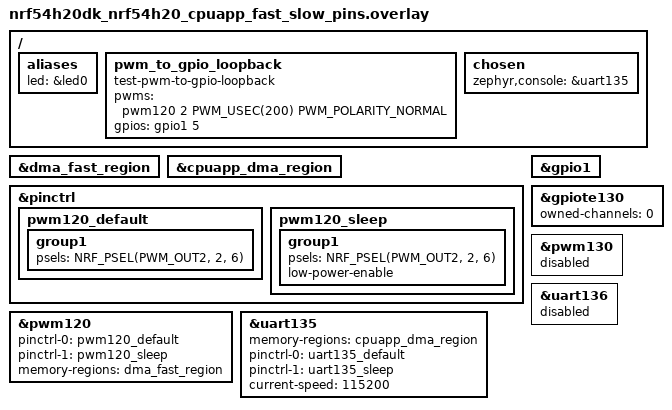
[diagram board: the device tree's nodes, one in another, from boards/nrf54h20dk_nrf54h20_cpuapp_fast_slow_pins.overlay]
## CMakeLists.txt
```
#
# Copyright (c) 2024 Nordic Semiconductor ASA
#
# SPDX-License-Identifier: LicenseRef-Nordic-5-Clause
#

cmake_minimum_required(VERSION 3.20.0)

find_package(Zephyr REQUIRED HINTS $ENV{ZEPHYR_BASE})

if(NOT SYSBUILD)
	message(FATAL_ERROR
		" This is a multi-image application that should be built using sysbuild.\n"
		" Add --sysbuild argument to west build command to prepare all the images.")
endif()

project(idle_pwm_loopback)

target_sources(app PRIVATE src/main.c)
```

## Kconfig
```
#
# Copyright (c) 2024 Nordic Semiconductor ASA
#
# SPDX-License-Identifier: LicenseRef-Nordic-5-Clause
#

config TEST_SLEEP_DURATION_MS
	int "Core sleep duration (miliseconds)"
	default 1000
	help
	  Set sleep duration to TEST_SLEEP_DURATION_MS miliseconds.
	  Based on the value of 'min-residency-us' specified for each power state defined in the DTS,
	  core enters the lowest possible power state.

choice GLOBAL_DOMAIN_CLOCK_FREQUENCY_OPTION
	prompt "Global domain clock frequency"
	default GLOBAL_DOMAIN_CLOCK_FREQUENCY_OPTION_320MHZ

config GLOBAL_DOMAIN_CLOCK_FREQUENCY_OPTION_320MHZ
	bool "320MHz"

config GLOBAL_DOMAIN_CLOCK_FREQUENCY_OPTION_256MHZ
	bool "256MHz"

config GLOBAL_DOMAIN_CLOCK_FREQUENCY_OPTION_128MHZ
	bool "128MHz"

config GLOBAL_DOMAIN_CLOCK_FREQUENCY_OPTION_64MHZ
	bool "64MHz"

endchoice

config GLOBAL_DOMAIN_CLOCK_FREQUENCY_MHZ
	int
	default 320 if GLOBAL_DOMAIN_CLOCK_FREQUENCY_OPTION_320MHZ
	default 256 if GLOBAL_DOMAIN_CLOCK_FREQUENCY_OPTION_256MHZ
	default 128 if GLOBAL_DOMAIN_CLOCK_FREQUENCY_OPTION_128MHZ
	default 64 if GLOBAL_DOMAIN_CLOCK_FREQUENCY_OPTION_64MHZ

config GLOBAL_DOMAIN_CLOCK_FREQUENCY_SWITCHING
	bool "Enable global domain frequency changing when driver is active"

source "Kconfig.zephyr"
```

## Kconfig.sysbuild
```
#
# Copyright (c) 2024 Nordic Semiconductor ASA
#
# SPDX-License-Identifier: LicenseRef-Nordic-5-Clause
#

source "share/sysbuild/Kconfig"

config REMOTE_GLOBAL_DOMAIN_CLOCK_FREQUENCY_SWITCHING
	bool "Enable global domain frequency changing from remote"
```

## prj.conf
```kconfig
CONFIG_PRINTK=y

CONFIG_LOG=y
CONFIG_ASSERT=y
CONFIG_PWM=y
CONFIG_GPIO=y

CONFIG_NRF_REGTOOL_VERBOSITY=1
```

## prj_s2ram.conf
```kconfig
CONFIG_PM=y
CONFIG_PM_S2RAM=y
CONFIG_PM_S2RAM_CUSTOM_MARKING=y
CONFIG_POWEROFF=y

CONFIG_PM_DEVICE=y
CONFIG_PM_DEVICE_RUNTIME=y

CONFIG_BOOT_BANNER=n
CONFIG_NCS_BOOT_BANNER=n
CONFIG_PRINTK=n
CONFIG_LOG=n
CONFIG_CONSOLE=n
CONFIG_UART_CONSOLE=n
CONFIG_SERIAL=n

CONFIG_ASSERT=y
CONFIG_PWM=y
CONFIG_GPIO=y
```

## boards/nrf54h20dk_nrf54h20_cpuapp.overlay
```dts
/*
 * Copyright (c) 2024 Nordic Semiconductor ASA
 *
 * SPDX-License-Identifier: LicenseRef-Nordic-5-Clause
 */

#include <zephyr/dt-bindings/pwm/pwm.h>
#include <zephyr/dt-bindings/gpio/nordic-nrf-gpio.h>

/* Test requires wire connection between:
 *  - PWM130 OUT[0] at P0.00
 *  - GPIO input at P0.01
 */

/ {
	aliases {
		led = &led0;
		/delete-property/ led1;
	};

	pwm_to_gpio_loopback: pwm_to_gpio_loopback {
		compatible = "test-pwm-to-gpio-loopback";
		pwms = <&pwm130 0 PWM_USEC(200) PWM_POLARITY_NORMAL>;
		gpios = <&gpio0 1 GPIO_ACTIVE_HIGH>;
	};
};

/delete-node/ &led1;

&pinctrl {
	/omit-if-no-ref/ pwm130_default: pwm130_default {
		group1 {
			psels = <NRF_PSEL(PWM_OUT0, 0, 0)>;
		};
	};
	/omit-if-no-ref/ pwm130_sleep: pwm130_sleep {
		group1 {
			psels = <NRF_PSEL(PWM_OUT0, 0, 0)>;
			low-power-enable;
		};
	};
};

&gpio0 {
	status = "okay";
};

&gpiote130 {
	status = "okay";
	owned-channels = <0>;
};

&pwm130 {
	status = "okay";
	pinctrl-0 = <&pwm130_default>;
	pinctrl-1 = <&pwm130_sleep>;
	pinctrl-names = "default", "sleep";
	memory-regions = <&cpuapp_dma_region>;
};
```

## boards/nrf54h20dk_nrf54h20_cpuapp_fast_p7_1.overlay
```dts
/*
 * Copyright (c) 2024 Nordic Semiconductor ASA
 *
 * SPDX-License-Identifier: LicenseRef-Nordic-5-Clause
 */

#include <zephyr/dt-bindings/pwm/pwm.h>
#include <zephyr/dt-bindings/gpio/nordic-nrf-gpio.h>

/* Test requires wire connection between:
 *  - PWM120 OUT[1] at P7.01
 *  - GPIO input at P1.05
 */

/ {
	aliases {
		led = &led0;
		/delete-property/ led1;
	};

	pwm_to_gpio_loopback: pwm_to_gpio_loopback {
		compatible = "test-pwm-to-gpio-loopback";
		pwms = <&pwm120 1 PWM_USEC(200) PWM_POLARITY_NORMAL>;
		gpios = <&gpio1 5 GPIO_ACTIVE_HIGH>;
	};
};

/delete-node/ &led1;

&pinctrl {
	/omit-if-no-ref/ pwm120_default: pwm120_default {
		group1 {
			psels = <NRF_PSEL(PWM_OUT1, 7, 1)>;
		};
	};
	/omit-if-no-ref/ pwm120_sleep: pwm120_sleep {
		group1 {
			psels = <NRF_PSEL(PWM_OUT1, 7, 1)>;
			low-power-enable;
		};
	};
};

&gpio1 {
	status = "okay";
};

&gpiote130 {
	status = "okay";
	owned-channels = <0>;
};

&pwm120 {
	status = "okay";
	pinctrl-0 = <&pwm120_default>;
	pinctrl-1 = <&pwm120_sleep>;
	pinctrl-names = "default", "sleep";
	memory-regions = <&dma_fast_region>;
};

&dma_fast_region {
	status = "okay";
};

&pwm130 {
	status = "disabled";
};
```

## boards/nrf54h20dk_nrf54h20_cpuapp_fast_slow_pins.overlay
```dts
/*
 * Copyright (c) 2024 Nordic Semiconductor ASA
 *
 * SPDX-License-Identifier: LicenseRef-Nordic-5-Clause
 */

#include <zephyr/dt-bindings/pwm/pwm.h>
#include <zephyr/dt-bindings/gpio/nordic-nrf-gpio.h>

/* Test requires wire connection between:
 *  - PWM120 OUT[2] at P2.06
 *  - GPIO input at P1.05
 */

/ {
	aliases {
		led = &led0;
		/delete-property/ led1;
	};

	pwm_to_gpio_loopback: pwm_to_gpio_loopback {
		compatible = "test-pwm-to-gpio-loopback";
		pwms = <&pwm120 2 PWM_USEC(200) PWM_POLARITY_NORMAL>;
		gpios = <&gpio1 5 GPIO_ACTIVE_HIGH>;
	};

	chosen {
		zephyr,console = &uart135;
	};
};

/delete-node/ &led1;

&dma_fast_region {
	status = "okay";
};

&cpuapp_dma_region {
	status = "okay";
};

&pinctrl {
	/omit-if-no-ref/ pwm120_default: pwm120_default {
		group1 {
			psels = <NRF_PSEL(PWM_OUT2, 2, 6)>;
		};
	};
	/omit-if-no-ref/ pwm120_sleep: pwm120_sleep {
		group1 {
			psels = <NRF_PSEL(PWM_OUT2, 2, 6)>;
			low-power-enable;
		};
	};
};

&gpio1 {
	status = "okay";
};

&gpiote130 {
	status = "okay";
	owned-channels = <0>;
};

&pwm120 {
	status = "okay";
	pinctrl-0 = <&pwm120_default>;
	pinctrl-1 = <&pwm120_sleep>;
	pinctrl-names = "default", "sleep";
	memory-regions = <&dma_fast_region>;
};

&pwm130 {
	status = "disabled";
};

&uart136 {
	status = "disabled";
	/delete-property/ memory-regions;
	/delete-property/ hw-flow-control;
};

&uart135 {
	status = "okay";
	memory-regions = <&cpuapp_dma_region>;
	pinctrl-0 = <&uart135_default>;
	pinctrl-1 = <&uart135_sleep>;
	pinctrl-names = "default", "sleep";
	current-speed = <115200>;
	/delete-property/ hw-flow-control;
};
```

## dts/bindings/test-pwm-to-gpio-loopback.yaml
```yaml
#
# Copyright (c) 2024 Nordic Semiconductor ASA
#
# SPDX-License-Identifier: LicenseRef-Nordic-5-Clause
#

description: |
    This binding provides resources required to build and run the
    tests/drivers/pwm/pwm_to_gpio_loopback test in Zephyr.

compatible: "test-pwm-to-gpio-loopback"

properties:
  pwms:
    type: phandle-array
    required: true
    description: |
      PWM pin that will be used for generating a pulse-width modulated signal.
  gpios:
    type: phandle-array
    required: true
    description: |
      GPIO pin will be used for capturing the generated signal. The PWM and GPIO
      pins must be physically connected to each other.
```

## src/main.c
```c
/*
 * Copyright (c) 2024 Nordic Semiconductor ASA
 *
 * SPDX-License-Identifier: LicenseRef-Nordic-5-Clause
 */

#include <zephyr/logging/log.h>
LOG_MODULE_REGISTER(idle_pwm_loop, LOG_LEVEL_INF);

#include <zephyr/kernel.h>
#include <zephyr/cache.h>
#include <zephyr/drivers/pwm.h>
#include <zephyr/drivers/gpio.h>
#include <zephyr/pm/device_runtime.h>

#if defined(CONFIG_CLOCK_CONTROL)
#include <zephyr/devicetree/clocks.h>
#include <zephyr/drivers/clock_control/nrf_clock_control.h>
#endif

#if !DT_NODE_EXISTS(DT_NODELABEL(pwm_to_gpio_loopback))
#error "Unsupported board: pwm_to_gpio_loopback node is not defined"
#endif

#define SHM_START_ADDR		(DT_REG_ADDR(DT_NODELABEL(cpuapp_cpurad_ipc_shm)))
volatile static uint32_t *shared_var = (volatile uint32_t *) SHM_START_ADDR;
#define HOST_IS_READY	(1)
#define REMOTE_IS_READY	(2)

static const struct gpio_dt_spec led = GPIO_DT_SPEC_GET(DT_ALIAS(led), gpios);

static const struct gpio_dt_spec pin_in = GPIO_DT_SPEC_GET_BY_IDX(
	DT_NODELABEL(pwm_to_gpio_loopback),	gpios, 0);

static const struct pwm_dt_spec pwm_out = PWM_DT_SPEC_GET(
	DT_NODELABEL(pwm_to_gpio_loopback));

static struct gpio_callback gpio_input_cb_data;
static volatile uint32_t high, low;

/* Variables used to make CPU active for ~1 second */
static struct k_timer my_timer;
static bool timer_expired;


#if defined(CONFIG_CLOCK_CONTROL)
const uint32_t freq[] = {320, 256, 128, 64};

/*
 * Set Global Domain frequency (HSFLL120)
 */
void set_global_domain_frequency(uint32_t freq)
{
	int err;
	int res;
	struct onoff_client cli;
	const struct device *hsfll_dev = DEVICE_DT_GET(DT_NODELABEL(hsfll120));
	const struct nrf_clock_spec clk_spec_global_hsfll = {.frequency = MHZ(freq)};

	printk("Requested frequency [Hz]: %d\n", clk_spec_global_hsfll.frequency);
	sys_notify_init_spinwait(&cli.notify);
	err = nrf_clock_control_request(hsfll_dev, &clk_spec_global_hsfll, &cli);
	__ASSERT((err >= 0 && err < 3), "Wrong nrf_clock_control_request return code");
	do {
		err = sys_notify_fetch_result(&cli.notify, &res);
		k_yield();
	} while (err == -EAGAIN);
	__ASSERT(err == 0, "Wrong clock control request return code");
	__ASSERT(res == 0, "Wrong clock control request response");
}
#endif /* CONFIG_CLOCK_CONTROL */

void my_timer_handler(struct k_timer *dummy)
{
	timer_expired = true;
}

void gpio_input_edge_callback(const struct device *dev, struct gpio_callback *cb, uint32_t pins)
{
	uint32_t pin = 0;

	while (pins >>= 1) {
		pin++;
	}

	if (gpio_pin_get(dev, pin)) {
		high++;
	} else {
		low++;
	}
}

int main(void)
{
	uint32_t counter = 0;
	uint32_t pulse;
	uint32_t edges;
	uint32_t tolerance;
	int ret;
	int test_repetitions = 3;

	ret = gpio_is_ready_dt(&led);
	__ASSERT(ret, "Error: GPIO Device not ready");

	ret = gpio_pin_configure_dt(&led, GPIO_OUTPUT_ACTIVE);
	__ASSERT(ret == 0, "Could not configure led GPIO");

	/* Wait a bit to solve NRFS request timeout issue. */
	k_msleep(100);

#if defined(CONFIG_CLOCK_CONTROL)
	set_global_domain_frequency(CONFIG_GLOBAL_DOMAIN_CLOCK_FREQUENCY_MHZ);
#endif

	/* Set PWM fill ratio to 50% */
	pulse = pwm_out.period >> 1;

	/* Calculate how many rising edges occur during 1 second of activity */
	edges = 1000000000 / pwm_out.period;

	/* Due to not perfect synchronization some edges may be lost.
	 * Set tolerance to 1% (or at least 1 edge).
	 */
	tolerance = edges / 100;
	if (tolerance == 0) {
		tolerance = 1;
	}

	LOG_INF("Multicore idle_pwm_loopback test on %s", CONFIG_BOARD_TARGET);
	LOG_INF("Core will sleep for %u ms", CONFIG_TEST_SLEEP_DURATION_MS);
	LOG_INF("Testing PWM device %s, channel %d", pwm_out.dev->name, pwm_out.channel);
	LOG_INF("GPIO loopback at %s, pin %d", pin_in.port->name, pin_in.pin);
	LOG_INF("Pulse/period: %u/%u usec", pulse / 1000, pwm_out.period / 1000);
	LOG_INF("Expected number of edges in 1 second: %u (+/- %u)", edges, tolerance);
	LOG_INF("Shared memory at %p", (void *) shared_var);
	LOG_INF("===================================================================");

	ret = pwm_is_ready_dt(&pwm_out);
	if (!ret) {
		LOG_ERR("Device %s is not ready.", pwm_out.dev->name);
	}
	__ASSERT_NO_MSG(ret);

	ret = gpio_is_ready_dt(&pin_in);
	if (!ret) {
		LOG_ERR("Device %s is not ready.", pin_in.port->name);
	}
	__ASSERT_NO_MSG(ret);

#if defined(CONFIG_PM_DEVICE_RUNTIME)
	pm_device_runtime_enable(pwm_out.dev);
#endif

	/* configure gpio and init GPIOTE callback */
	ret = gpio_pin_configure_dt(&pin_in, GPIO_INPUT);
	if (ret) {
		LOG_ERR("gpio_pin_configure_dt() has failed (%d)", ret);
	}
	__ASSERT_NO_MSG(ret == 0);

	gpio_init_callback(&gpio_input_cb_data, gpio_input_edge_callback, BIT(pin_in.pin));

	k_timer_init(&my_timer, my_timer_handler, NULL);

	/* Synchronize Remote core with Host core */
#if !defined(CONFIG_TEST_ROLE_REMOTE)
	LOG_DBG("HOST starts");
	*shared_var = HOST_IS_READY;
	sys_cache_data_flush_range((void *) shared_var, sizeof(*shared_var));
	LOG_DBG("HOST wrote HOST_IS_READY: %u", *shared_var);
	while (*shared_var != REMOTE_IS_READY) {
		k_msleep(1);
		sys_cache_data_invd_range((void *) shared_var, sizeof(*shared_var));
		LOG_DBG("shared_var is: %u", *shared_var);
	}
	LOG_DBG("HOST continues");
#else
	LOG_DBG("REMOTE starts");
	while (*shared_var != HOST_IS_READY) {
		k_msleep(1);
		sys_cache_data_invd_range((void *) shared_var, sizeof(*shared_var));
		LOG_DBG("shared_var is: %u", *shared_var);
	}
	LOG_DBG("REMOTE found that HOST_IS_READY");
	*shared_var = REMOTE_IS_READY;
	sys_cache_data_flush_range((void *) shared_var, sizeof(*shared_var));
	LOG_DBG("REMOTE wrote REMOTE_IS_READY: %u", *shared_var);
	LOG_DBG("REMOTE continues");
#endif

#if defined(CONFIG_COVERAGE)
	printk("Coverage analysis enabled\n");
	while (test_repetitions--)
#else
	/* Run test forever. */
	while (test_repetitions)
#endif
	{
		timer_expired = false;

		/* clear edge counters */
		high = 0;
		low = 0;

		/* start a one-shot timer that expires after 1 second */
		k_timer_start(&my_timer, K_MSEC(1000), K_NO_WAIT);

		/* configure and enable GPIOTE */
		ret = gpio_pin_interrupt_configure_dt(&pin_in, GPIO_INT_EDGE_BOTH);
		if (ret) {
			LOG_ERR("gpio_pin_interrupt_configure_dt() has failed (%d)", ret);
		}
		__ASSERT_NO_MSG(ret == 0);

		ret = gpio_add_callback(pin_in.port, &gpio_input_cb_data);
		if (ret) {
			LOG_ERR("gpio_add_callback() has failed (%d)", ret);
		}
		__ASSERT_NO_MSG(ret == 0);

		/* configure and enable PWM */
#if defined(CONFIG_PM_DEVICE_RUNTIME)
		pm_device_runtime_get(pwm_out.dev);
#endif
		ret = pwm_set_dt(&pwm_out, pwm_out.period, pulse);
		if (ret) {
			LOG_ERR("pwm_set_dt(%u, %u) returned %d",
				pwm_out.period, pulse, ret);
		}
		__ASSERT_NO_MSG(ret == 0);

#if defined(CONFIG_GLOBAL_DOMAIN_CLOCK_FREQUENCY_SWITCHING)
			k_busy_wait(100000);
			set_global_domain_frequency(freq[counter % ARRAY_SIZE(freq)]);
#endif
		/* Keep PWM active for ~ 1 second */
		while (!timer_expired) {
			/* GPIOTE shall count edges here */
			k_busy_wait(10000);
		}

		/* Disable PWM */
		ret = pwm_set_dt(&pwm_out, 0, 0);
		if (ret) {
			LOG_ERR("pwm_set_dt(%u, %u) returned %d",
				0, 0, ret);
			return ret;
		}
#if defined(CONFIG_PM_DEVICE_RUNTIME)
		pm_device_runtime_put(pwm_out.dev);
#endif

		/* Disable GPIOTE interrupt */
		ret = gpio_remove_callback(pin_in.port, &gpio_input_cb_data);
		if (ret) {
			LOG_ERR("gpio_remove_callback() has failed (%d)", ret);
		}
		__ASSERT_NO_MSG(ret == 0);

		ret = gpio_pin_interrupt_configure_dt(&pin_in, GPIO_INT_DISABLE |
				GPIO_INT_LEVELS_LOGICAL | GPIO_INT_HIGH_1);
		if (ret) {
			LOG_ERR("gpio_pin_interrupt_configure_dt() has failed (%d)", ret);
		}
		__ASSERT_NO_MSG(ret == 0);

		LOG_INF("Iteration %u: rising: %u, falling %u",
			counter, high, low);

		/* Check if PWM is working */
		__ASSERT_NO_MSG(high >= edges - tolerance);
		__ASSERT_NO_MSG(low >= edges - tolerance);

		/* Sleep / enter low power state */
		gpio_pin_set_dt(&led, 0);
		k_msleep(CONFIG_TEST_SLEEP_DURATION_MS);
		gpio_pin_set_dt(&led, 1);
		counter++;
	}

#if defined(CONFIG_COVERAGE)
	printk("Coverage analysis start\n");
#endif
	return 0;
}
```
